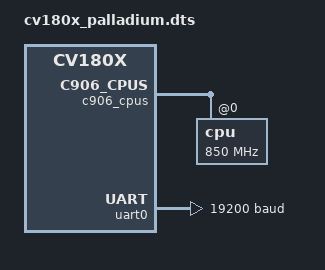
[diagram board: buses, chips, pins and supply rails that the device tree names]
/dts-v1/;
#include "cv180x_base_riscv.dtsi"
#include "cv180x_asic_bga.dtsi"
#include "cv180x_asic_spinor.dtsi"
#include "cv180x_default_memmap.dtsi"

/ {

};

&c906_cpus {
	timebase-frequency = <1000000000>;

	cpu@0 {
		clock-frequency = <850000000>;
	};
};

&uart0 {
	clock-frequency = <307200>;
	current-speed = <19200>;
};
